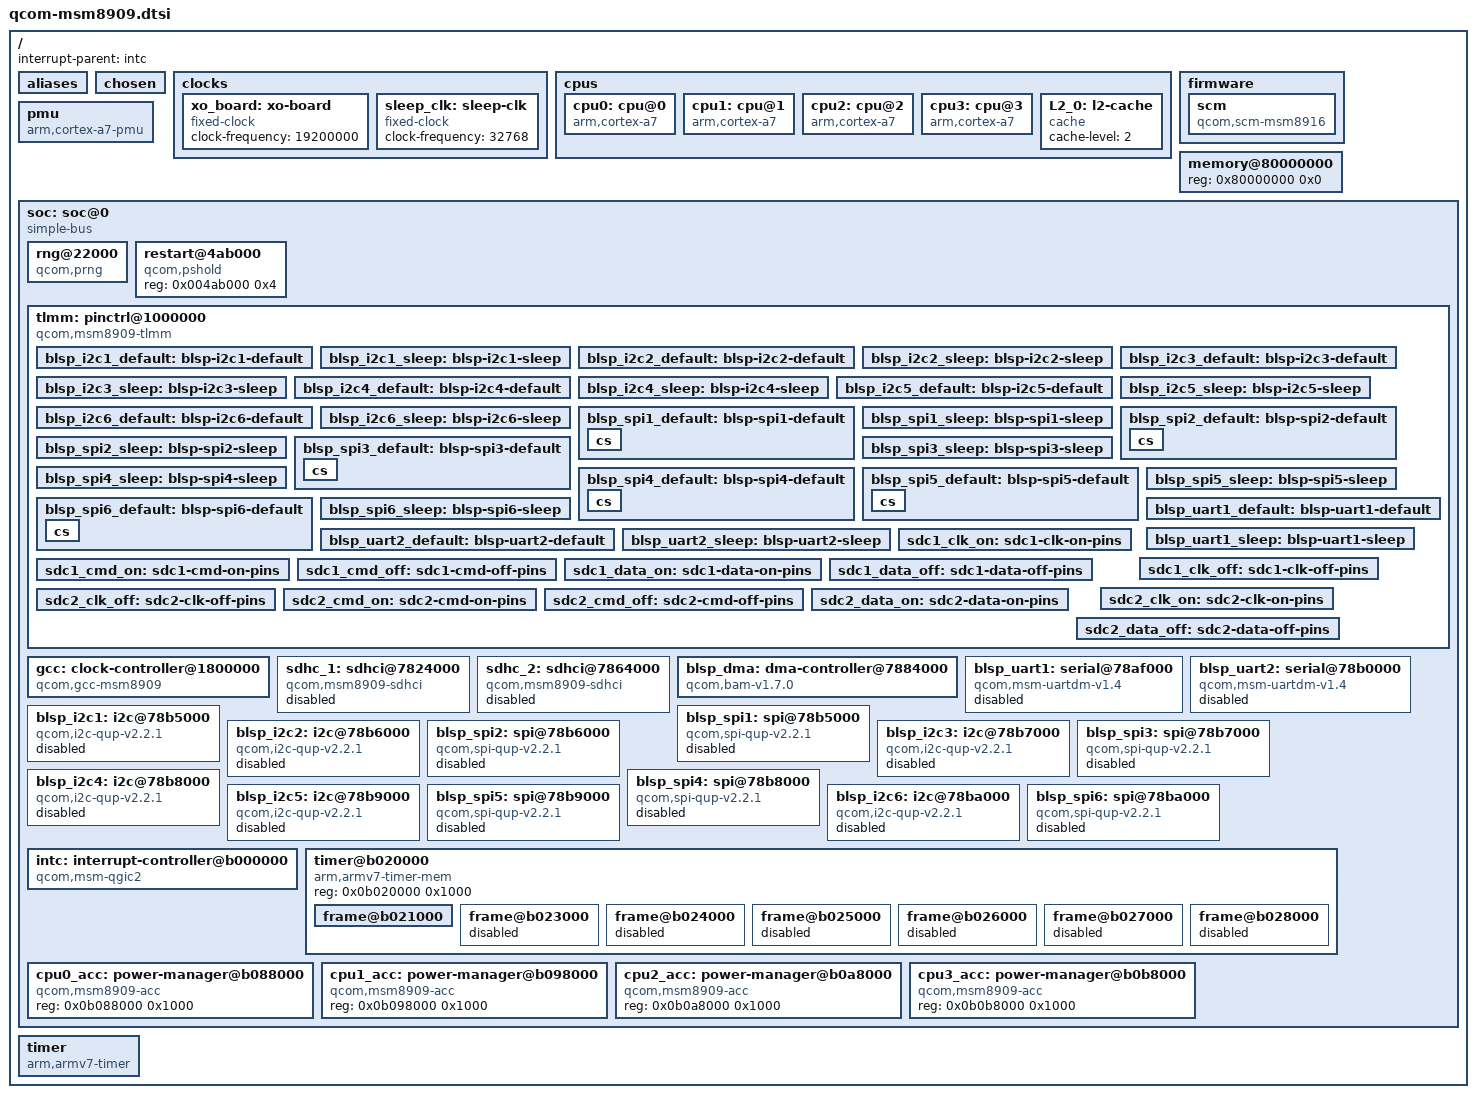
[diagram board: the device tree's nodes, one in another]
// SPDX-License-Identifier: GPL-2.0-only
/*
 * Copyright (c) 2014-2019, The Linux Foundation. All rights reserved.
 */
/dts-v1/;

#include <dt-bindings/clock/qcom,gcc-msm8909.h>
#include <dt-bindings/gpio/gpio.h>
#include <dt-bindings/interrupt-controller/arm-gic.h>

/ {
	#address-cells = <1>;
	#size-cells = <1>;
	interrupt-parent = <&intc>;

	aliases {
		mmc0 = &sdhc_1; /* SDC1 eMMC slot */
		mmc1 = &sdhc_2; /* SDC2 SD card slot */
	};

	chosen { };

	clocks {
		xo_board: xo-board {
			compatible = "fixed-clock";
			#clock-cells = <0>;
			clock-frequency = <19200000>;
		};

		sleep_clk: sleep-clk {
			compatible = "fixed-clock";
			#clock-cells = <0>;
			clock-frequency = <32768>;
		};
	};

	cpus {
		#address-cells = <1>;
		#size-cells = <0>;

		cpu0: cpu@0 {
			device_type = "cpu";
			compatible = "arm,cortex-a7";
			reg = <0x0>;
			next-level-cache = <&L2_0>;
			enable-method = "qcom,msm8909-smp";
			qcom,acc = <&cpu0_acc>;
		};

		cpu1: cpu@1 {
			device_type = "cpu";
			compatible = "arm,cortex-a7";
			reg = <0x1>;
			next-level-cache = <&L2_0>;
			enable-method = "qcom,msm8909-smp";
			qcom,acc = <&cpu1_acc>;
		};

		cpu2: cpu@2 {
			device_type = "cpu";
			compatible = "arm,cortex-a7";
			reg = <0x2>;
			next-level-cache = <&L2_0>;
			enable-method = "qcom,msm8909-smp";
			qcom,acc = <&cpu2_acc>;
		};

		cpu3: cpu@3 {
			device_type = "cpu";
			compatible = "arm,cortex-a7";
			reg = <0x3>;
			next-level-cache = <&L2_0>;
			enable-method = "qcom,msm8909-smp";
			qcom,acc = <&cpu3_acc>;
		};

		L2_0: l2-cache {
			compatible = "cache";
			cache-level = <2>;
		};
	};

	firmware {
		scm: scm {
			compatible = "qcom,scm-msm8916", "qcom,scm";
			clocks = <&gcc GCC_CRYPTO_CLK>,
				 <&gcc GCC_CRYPTO_AXI_CLK>,
				 <&gcc GCC_CRYPTO_AHB_CLK>;
			clock-names = "core", "bus", "iface";
			qcom,dload-mode = <&tcsr 0x6100>;
		};
	};

	memory@80000000 {
		device_type = "memory";
		/* We expect the bootloader to fill in the reg */
		reg = <0x80000000 0x0>;
	};

	pmu {
		compatible = "arm,cortex-a7-pmu";
		interrupts = <GIC_PPI 7 (GIC_CPU_MASK_SIMPLE(4) | IRQ_TYPE_LEVEL_HIGH)>;
	};

	soc: soc@0 {
		compatible = "simple-bus";
		#address-cells = <1>;
		#size-cells = <1>;
		ranges;

		rng@22000 {
			compatible = "qcom,prng";
			reg = <0x00022000 0x200>;
			clocks = <&gcc GCC_PRNG_AHB_CLK>;
			clock-names = "core";
		};

		restart@4ab000 {
			compatible = "qcom,pshold";
			reg = <0x004ab000 0x4>;
		};

		tlmm: pinctrl@1000000 {
			compatible = "qcom,msm8909-tlmm";
			reg = <0x01000000 0x300000>;
			interrupts = <GIC_SPI 208 IRQ_TYPE_LEVEL_HIGH>;
			gpio-controller;
			#gpio-cells = <2>;
			gpio-ranges = <&tlmm 0 0 117>;
			interrupt-controller;
			#interrupt-cells = <2>;

			blsp_i2c1_default: blsp-i2c1-default {
				pins = "gpio6", "gpio7";
				function = "blsp_i2c1";

				drive-strength = <2>;
				bias-disable;
			};

			blsp_i2c1_sleep: blsp-i2c1-sleep {
				pins = "gpio6", "gpio7";
				function = "gpio";

				drive-strength = <2>;
				bias-disable;
			};

			blsp_i2c2_default: blsp-i2c2-default {
				pins = "gpio111", "gpio112";
				function = "blsp_i2c2";

				drive-strength = <2>;
				bias-disable;
			};

			blsp_i2c2_sleep: blsp-i2c2-sleep {
				pins = "gpio111", "gpio112";
				function = "gpio";

				drive-strength = <2>;
				bias-disable;
			};

			blsp_i2c3_default: blsp-i2c3-default {
				pins = "gpio29", "gpio30";
				function = "blsp_i2c3";

				drive-strength = <2>;
				bias-disable;
			};

			blsp_i2c3_sleep: blsp-i2c3-sleep {
				pins = "gpio29", "gpio30";
				function = "gpio";

				drive-strength = <2>;
				bias-disable;
			};

			blsp_i2c4_default: blsp-i2c4-default {
				pins = "gpio14", "gpio15";
				function = "blsp_i2c4";

				drive-strength = <2>;
				bias-disable;
			};

			blsp_i2c4_sleep: blsp-i2c4-sleep {
				pins = "gpio14", "gpio15";
				function = "gpio";

				drive-strength = <2>;
				bias-disable;
			};

			blsp_i2c5_default: blsp-i2c5-default {
				pins = "gpio18", "gpio19";
				function = "blsp_i2c5";

				drive-strength = <2>;
				bias-disable;
			};

			blsp_i2c5_sleep: blsp-i2c5-sleep {
				pins = "gpio18", "gpio19";
				function = "gpio";

				drive-strength = <2>;
				bias-disable;
			};

			blsp_i2c6_default: blsp-i2c6-default {
				pins = "gpio10", "gpio11";
				function = "blsp_i2c6";

				drive-strength = <2>;
				bias-disable;
			};

			blsp_i2c6_sleep: blsp-i2c6-sleep {
				pins = "gpio10", "gpio11";
				function = "gpio";

				drive-strength = <2>;
				bias-disable;
			};

			blsp_spi1_default: blsp-spi1-default {
				pins = "gpio4", "gpio5", "gpio7";
				function = "blsp_spi1";

				drive-strength = <12>;
				bias-disable;

				cs {
					pins = "gpio6";
					function = "gpio";

					drive-strength = <2>;
					bias-disable;
					output-high;
				};
			};

			blsp_spi1_sleep: blsp-spi1-sleep {
				pins = "gpio4", "gpio5", "gpio6", "gpio7";
				function = "gpio";

				drive-strength = <2>;
				bias-pull-down;
			};

			blsp_spi2_default: blsp-spi2-default {
				pins = "gpio20", "gpio21", "gpio112";
				function = "blsp_spi2";

				drive-strength = <12>;
				bias-disable;

				cs {
					pins = "gpio111";
					function = "gpio";

					drive-strength = <2>;
					bias-disable;
					output-high;
				};
			};

			blsp_spi2_sleep: blsp-spi2-sleep {
				pins = "gpio20", "gpio21", "gpio111", "gpio112";
				function = "gpio";

				drive-strength = <2>;
				bias-pull-down;
			};

			blsp_spi3_default: blsp-spi3-default {
				pins = "gpio0", "gpio1", "gpio3";
				function = "blsp_spi3";

				drive-strength = <12>;
				bias-disable;

				cs {
					pins = "gpio2";
					function = "gpio";

					drive-strength = <2>;
					bias-disable;
					output-high;
				};
			};

			blsp_spi3_sleep: blsp-spi3-sleep {
				pins = "gpio0", "gpio1", "gpio2", "gpio3";
				function = "gpio";

				drive-strength = <2>;
				bias-pull-down;
			};

			blsp_spi4_default: blsp-spi4-default {
				pins = "gpio12", "gpio13", "gpio15";
				function = "blsp_spi4";

				drive-strength = <12>;
				bias-disable;

				cs {
					pins = "gpio14";
					function = "gpio";

					drive-strength = <2>;
					bias-disable;
					output-high;
				};
			};

			blsp_spi4_sleep: blsp-spi4-sleep {
				pins = "gpio12", "gpio13", "gpio14", "gpio15";
				function = "gpio";

				drive-strength = <2>;
				bias-pull-down;
			};

			blsp_spi5_default: blsp-spi5-default {
				pins = "gpio16", "gpio17", "gpio19";
				function = "blsp_spi5";

				drive-strength = <12>;
				bias-disable;

				cs {
					pins = "gpio18";
					function = "gpio";

					drive-strength = <2>;
					bias-disable;
					output-high;
				};
			};

			blsp_spi5_sleep: blsp-spi5-sleep {
				pins = "gpio16", "gpio17", "gpio18", "gpio19";
				function = "gpio";

				drive-strength = <2>;
				bias-pull-down;
			};

			blsp_spi6_default: blsp-spi6-default {
				pins = "gpio8", "gpio9", "gpio11";
				function = "blsp_spi6";

				drive-strength = <12>;
				bias-disable;

				cs {
					pins = "gpio10";
					function = "gpio";

					drive-strength = <2>;
					bias-disable;
					output-high;
				};
			};

			blsp_spi6_sleep: blsp-spi6-sleep {
				pins = "gpio8", "gpio9", "gpio10", "gpio11";
				function = "gpio";

				drive-strength = <2>;
				bias-pull-down;
			};

			blsp_uart1_default: blsp-uart1-default {
				pins = "gpio4", "gpio5";
				function = "blsp_uart1";

				drive-strength = <2>;
				bias-disable;
			};

			blsp_uart1_sleep: blsp-uart1-sleep {
				pins = "gpio4", "gpio5";
				function = "gpio";

				drive-strength = <2>;
				bias-pull-down;
			};

			blsp_uart2_default: blsp-uart2-default {
				pins = "gpio20", "gpio21";
				function = "blsp_uart2";

				drive-strength = <2>;
				bias-disable;
			};

			blsp_uart2_sleep: blsp-uart2-sleep {
				pins = "gpio20", "gpio21";
				function = "gpio";

				drive-strength = <2>;
				bias-pull-down;
			};

			sdc1_clk_on: sdc1-clk-on-pins {
				pins = "sdc1_clk";
				bias-disable;
				drive-strength = <16>;
			};

			sdc1_clk_off: sdc1-clk-off-pins {
				pins = "sdc1_clk";
				bias-disable;
				drive-strength = <2>;
			};

			sdc1_cmd_on: sdc1-cmd-on-pins {
				pins = "sdc1_cmd";
				bias-disable;
				drive-strength = <10>;
			};

			sdc1_cmd_off: sdc1-cmd-off-pins {
				pins = "sdc1_cmd";
				bias-disable;
				drive-strength = <2>;
			};

			sdc1_data_on: sdc1-data-on-pins {
				pins = "sdc1_data";
				bias-pull-up;
				drive-strength = <10>;
			};

			sdc1_data_off: sdc1-data-off-pins {
				pins = "sdc1_data";
				bias-pull-up;
				drive-strength = <2>;
			};

			sdc2_clk_on: sdc2-clk-on-pins {
				pins = "sdc2_clk";
				drive-strength = <16>;
				bias-disable;
			};

			sdc2_clk_off: sdc2-clk-off-pins {
				pins = "sdc2_clk";
				bias-disable;
				drive-strength = <2>;
			};

			sdc2_cmd_on: sdc2-cmd-on-pins {
				pins = "sdc2_cmd";
				bias-pull-up;
				drive-strength = <10>;
			};

			sdc2_cmd_off: sdc2-cmd-off-pins {
				pins = "sdc2_cmd";
				bias-pull-up;
				drive-strength = <2>;
			};

			sdc2_data_on: sdc2-data-on-pins {
				pins = "sdc2_data";
				bias-pull-up;
				drive-strength = <10>;
			};

			sdc2_data_off: sdc2-data-off-pins {
				pins = "sdc2_data";
				bias-pull-up;
				drive-strength = <2>;
			};
		};

		gcc: clock-controller@1800000 {
			compatible = "qcom,gcc-msm8909";
			reg = <0x01800000 0x80000>;
			#clock-cells = <1>;
			#reset-cells = <1>;
			#power-domain-cells = <1>;
			clocks = <&xo_board>, <&sleep_clk>, <0>, <0>;
			clock-names = "xo", "sleep_clk", "dsi0pll", "dsi0pllbyte";
		};

		sdhc_1: sdhci@7824000 {
			compatible = "qcom,msm8909-sdhci", "qcom,sdhci-msm-v4";
			reg = <0x07824900 0x11c>, <0x07824000 0x800>;
			reg-names = "hc_mem", "core_mem";

			interrupts = <GIC_SPI 123 IRQ_TYPE_LEVEL_HIGH>,
				     <GIC_SPI 138 IRQ_TYPE_LEVEL_HIGH>;
			interrupt-names = "hc_irq", "pwr_irq";
			clocks = <&gcc GCC_SDCC1_APPS_CLK>,
				 <&gcc GCC_SDCC1_AHB_CLK>,
				 <&xo_board>;
			clock-names = "core", "iface", "xo";

			pinctrl-names = "default", "sleep";
			pinctrl-0 = <&sdc1_clk_on &sdc1_cmd_on &sdc1_data_on>;
			pinctrl-1 = <&sdc1_clk_off &sdc1_cmd_off &sdc1_data_off>;

			mmc-hs200-1_8v;
			mmc-ddr-1_8v;
			bus-width = <8>;
			non-removable;
			status = "disabled";
		};

		sdhc_2: sdhci@7864000 {
			compatible = "qcom,msm8909-sdhci", "qcom,sdhci-msm-v4";
			reg = <0x07864900 0x11c>, <0x07864000 0x800>;
			reg-names = "hc_mem", "core_mem";

			interrupts = <GIC_SPI 125 IRQ_TYPE_LEVEL_HIGH>,
				     <GIC_SPI 221 IRQ_TYPE_LEVEL_HIGH>;
			interrupt-names = "hc_irq", "pwr_irq";
			clocks = <&gcc GCC_SDCC2_APPS_CLK>,
				 <&gcc GCC_SDCC2_AHB_CLK>,
				 <&xo_board>;
			clock-names = "core", "iface", "xo";

			pinctrl-names = "default", "sleep";
			pinctrl-0 = <&sdc2_clk_on &sdc2_cmd_on &sdc2_data_on>;
			pinctrl-1 = <&sdc2_clk_off &sdc2_cmd_off &sdc2_data_off>;

			bus-width = <4>;
			status = "disabled";
		};

		blsp_dma: dma-controller@7884000 {
			compatible = "qcom,bam-v1.7.0";
			reg = <0x07884000 0x23000>;
			interrupts = <GIC_SPI 238 IRQ_TYPE_LEVEL_HIGH>;
			clocks = <&gcc GCC_BLSP1_AHB_CLK>;
			clock-names = "bam_clk";
			#dma-cells = <1>;
			qcom,ee = <0>;
		};

		blsp_uart1: serial@78af000 {
			compatible = "qcom,msm-uartdm-v1.4", "qcom,msm-uartdm";
			reg = <0x078af000 0x200>;
			interrupts = <GIC_SPI 107 IRQ_TYPE_LEVEL_HIGH>;
			clocks = <&gcc GCC_BLSP1_UART1_APPS_CLK>,
				 <&gcc GCC_BLSP1_AHB_CLK>;
			clock-names = "core", "iface";
			dmas = <&blsp_dma 0>, <&blsp_dma 1>;
			dma-names = "tx", "rx";
			pinctrl-names = "default", "sleep";
			pinctrl-0 = <&blsp_uart1_default>;
			pinctrl-1 = <&blsp_uart1_sleep>;
			status = "disabled";
		};

		blsp_uart2: serial@78b0000 {
			compatible = "qcom,msm-uartdm-v1.4", "qcom,msm-uartdm";
			reg = <0x078b0000 0x200>;
			interrupts = <GIC_SPI 108 IRQ_TYPE_LEVEL_HIGH>;
			clocks = <&gcc GCC_BLSP1_UART2_APPS_CLK>,
				 <&gcc GCC_BLSP1_AHB_CLK>;
			clock-names = "core", "iface";
			dmas = <&blsp_dma 2>, <&blsp_dma 3>;
			dma-names = "tx", "rx";
			pinctrl-names = "default", "sleep";
			pinctrl-0 = <&blsp_uart2_default>;
			pinctrl-1 = <&blsp_uart2_sleep>;
			status = "disabled";
		};

		blsp_i2c1: i2c@78b5000 {
			compatible = "qcom,i2c-qup-v2.2.1";
			reg = <0x078b5000 0x500>;
			interrupts = <GIC_SPI 95 IRQ_TYPE_LEVEL_HIGH>;
			clocks = <&gcc GCC_BLSP1_QUP1_I2C_APPS_CLK>,
				 <&gcc GCC_BLSP1_AHB_CLK>;
			clock-names = "core", "iface";
			dmas = <&blsp_dma 4>, <&blsp_dma 5>;
			dma-names = "tx", "rx";
			pinctrl-names = "default", "sleep";
			pinctrl-0 = <&blsp_i2c1_default>;
			pinctrl-1 = <&blsp_i2c1_sleep>;
			#address-cells = <1>;
			#size-cells = <0>;
			status = "disabled";
		};

		blsp_spi1: spi@78b5000 {
			compatible = "qcom,spi-qup-v2.2.1";
			reg = <0x078b5000 0x500>;
			interrupts = <GIC_SPI 95 IRQ_TYPE_LEVEL_HIGH>;
			clocks = <&gcc GCC_BLSP1_QUP1_SPI_APPS_CLK>,
				 <&gcc GCC_BLSP1_AHB_CLK>;
			clock-names = "core", "iface";
			dmas = <&blsp_dma 4>, <&blsp_dma 5>;
			dma-names = "tx", "rx";
			pinctrl-names = "default", "sleep";
			pinctrl-0 = <&blsp_spi1_default>;
			pinctrl-1 = <&blsp_spi1_sleep>;
			#address-cells = <1>;
			#size-cells = <0>;
			status = "disabled";
		};

		blsp_i2c2: i2c@78b6000 {
			compatible = "qcom,i2c-qup-v2.2.1";
			reg = <0x078b6000 0x500>;
			interrupts = <GIC_SPI 96 IRQ_TYPE_LEVEL_HIGH>;
			clocks = <&gcc GCC_BLSP1_QUP2_I2C_APPS_CLK>,
				 <&gcc GCC_BLSP1_AHB_CLK>;
			clock-names = "core", "iface";
			dmas = <&blsp_dma 6>, <&blsp_dma 7>;
			dma-names = "tx", "rx";
			pinctrl-names = "default", "sleep";
			pinctrl-0 = <&blsp_i2c2_default>;
			pinctrl-1 = <&blsp_i2c2_sleep>;
			#address-cells = <1>;
			#size-cells = <0>;
			status = "disabled";
		};

		blsp_spi2: spi@78b6000 {
			compatible = "qcom,spi-qup-v2.2.1";
			reg = <0x078b6000 0x500>;
			interrupts = <GIC_SPI 96 IRQ_TYPE_LEVEL_HIGH>;
			clocks = <&gcc GCC_BLSP1_QUP2_SPI_APPS_CLK>,
				 <&gcc GCC_BLSP1_AHB_CLK>;
			clock-names = "core", "iface";
			dmas = <&blsp_dma 6>, <&blsp_dma 7>;
			dma-names = "tx", "rx";
			pinctrl-names = "default", "sleep";
			pinctrl-0 = <&blsp_spi2_default>;
			pinctrl-1 = <&blsp_spi2_sleep>;
			#address-cells = <1>;
			#size-cells = <0>;
			status = "disabled";
		};

		blsp_i2c3: i2c@78b7000 {
			compatible = "qcom,i2c-qup-v2.2.1";
			reg = <0x078b7000 0x500>;
			interrupts = <GIC_SPI 97 IRQ_TYPE_LEVEL_HIGH>;
			clocks = <&gcc GCC_BLSP1_QUP3_I2C_APPS_CLK>,
				 <&gcc GCC_BLSP1_AHB_CLK>;
			clock-names = "core", "iface";
			dmas = <&blsp_dma 8>, <&blsp_dma 9>;
			dma-names = "tx", "rx";
			pinctrl-names = "default", "sleep";
			pinctrl-0 = <&blsp_i2c3_default>;
			pinctrl-1 = <&blsp_i2c3_sleep>;
			#address-cells = <1>;
			#size-cells = <0>;
			status = "disabled";
		};

		blsp_spi3: spi@78b7000 {
			compatible = "qcom,spi-qup-v2.2.1";
			reg = <0x078b7000 0x500>;
			interrupts = <GIC_SPI 97 IRQ_TYPE_LEVEL_HIGH>;
			clocks = <&gcc GCC_BLSP1_QUP3_SPI_APPS_CLK>,
				 <&gcc GCC_BLSP1_AHB_CLK>;
			clock-names = "core", "iface";
			dmas = <&blsp_dma 8>, <&blsp_dma 9>;
			dma-names = "tx", "rx";
			pinctrl-names = "default", "sleep";
			pinctrl-0 = <&blsp_spi3_default>;
			pinctrl-1 = <&blsp_spi3_sleep>;
			#address-cells = <1>;
			#size-cells = <0>;
			status = "disabled";
		};

		blsp_i2c4: i2c@78b8000 {
			compatible = "qcom,i2c-qup-v2.2.1";
			reg = <0x078b8000 0x500>;
			interrupts = <GIC_SPI 98 IRQ_TYPE_LEVEL_HIGH>;
			clocks = <&gcc GCC_BLSP1_QUP4_I2C_APPS_CLK>,
				 <&gcc GCC_BLSP1_AHB_CLK>;
			clock-names = "core", "iface";
			dmas = <&blsp_dma 10>, <&blsp_dma 11>;
			dma-names = "tx", "rx";
			pinctrl-names = "default", "sleep";
			pinctrl-0 = <&blsp_i2c4_default>;
			pinctrl-1 = <&blsp_i2c4_sleep>;
			#address-cells = <1>;
			#size-cells = <0>;
			status = "disabled";
		};

		blsp_spi4: spi@78b8000 {
			compatible = "qcom,spi-qup-v2.2.1";
			reg = <0x078b8000 0x500>;
			interrupts = <GIC_SPI 98 IRQ_TYPE_LEVEL_HIGH>;
			clocks = <&gcc GCC_BLSP1_QUP4_SPI_APPS_CLK>,
				 <&gcc GCC_BLSP1_AHB_CLK>;
			clock-names = "core", "iface";
			dmas = <&blsp_dma 10>, <&blsp_dma 11>;
			dma-names = "tx", "rx";
			pinctrl-names = "default", "sleep";
			pinctrl-0 = <&blsp_spi4_default>;
			pinctrl-1 = <&blsp_spi4_sleep>;
			#address-cells = <1>;
			#size-cells = <0>;
			status = "disabled";
		};

		blsp_i2c5: i2c@78b9000 {
			compatible = "qcom,i2c-qup-v2.2.1";
			reg = <0x078b9000 0x500>;
			interrupts = <GIC_SPI 99 IRQ_TYPE_LEVEL_HIGH>;
			clocks = <&gcc GCC_BLSP1_QUP5_I2C_APPS_CLK>,
				 <&gcc GCC_BLSP1_AHB_CLK>;
			clock-names = "core", "iface";
			dmas = <&blsp_dma 12>, <&blsp_dma 13>;
			dma-names = "tx", "rx";
			pinctrl-names = "default", "sleep";
			pinctrl-0 = <&blsp_i2c5_default>;
			pinctrl-1 = <&blsp_i2c5_sleep>;
			#address-cells = <1>;
			#size-cells = <0>;
			status = "disabled";
		};

		blsp_spi5: spi@78b9000 {
			compatible = "qcom,spi-qup-v2.2.1";
			reg = <0x078b9000 0x500>;
			interrupts = <GIC_SPI 99 IRQ_TYPE_LEVEL_HIGH>;
			clocks = <&gcc GCC_BLSP1_QUP5_SPI_APPS_CLK>,
				 <&gcc GCC_BLSP1_AHB_CLK>;
			clock-names = "core", "iface";
			dmas = <&blsp_dma 12>, <&blsp_dma 13>;
			dma-names = "tx", "rx";
			pinctrl-names = "default", "sleep";
			pinctrl-0 = <&blsp_spi5_default>;
			pinctrl-1 = <&blsp_spi5_sleep>;
			#address-cells = <1>;
			#size-cells = <0>;
			status = "disabled";
		};

		blsp_i2c6: i2c@78ba000 {
			compatible = "qcom,i2c-qup-v2.2.1";
			reg = <0x078ba000 0x500>;
			interrupts = <GIC_SPI 100 IRQ_TYPE_LEVEL_HIGH>;
			clocks = <&gcc GCC_BLSP1_QUP6_I2C_APPS_CLK>,
				 <&gcc GCC_BLSP1_AHB_CLK>;
			clock-names = "core", "iface";
			dmas = <&blsp_dma 14>, <&blsp_dma 15>;
			dma-names = "tx", "rx";
			pinctrl-names = "default", "sleep";
			pinctrl-0 = <&blsp_i2c6_default>;
			pinctrl-1 = <&blsp_i2c6_sleep>;
			#address-cells = <1>;
			#size-cells = <0>;
			status = "disabled";
		};

		blsp_spi6: spi@78ba000 {
			compatible = "qcom,spi-qup-v2.2.1";
			reg = <0x078ba000 0x500>;
			interrupts = <GIC_SPI 100 IRQ_TYPE_LEVEL_HIGH>;
			clocks = <&gcc GCC_BLSP1_QUP6_SPI_APPS_CLK>,
				 <&gcc GCC_BLSP1_AHB_CLK>;
			clock-names = "core", "iface";
			dmas = <&blsp_dma 14>, <&blsp_dma 15>;
			dma-names = "tx", "rx";
			pinctrl-names = "default", "sleep";
			pinctrl-0 = <&blsp_spi6_default>;
			pinctrl-1 = <&blsp_spi6_sleep>;
			#address-cells = <1>;
			#size-cells = <0>;
			status = "disabled";
		};

		intc: interrupt-controller@b000000 {
			compatible = "qcom,msm-qgic2";
			reg = <0x0b000000 0x1000>,
			      <0x0b002000 0x1000>;
			interrupt-controller;
			#interrupt-cells = <3>;
		};

		timer@b020000 {
			compatible = "arm,armv7-timer-mem";
			reg = <0x0b020000 0x1000>;
			#address-cells = <1>;
			#size-cells = <1>;
			ranges;

			frame@b021000 {
				reg = <0x0b021000 0x1000>, <0x0b022000 0x1000>;
				interrupts = <GIC_SPI 8 IRQ_TYPE_LEVEL_HIGH>,
					     <GIC_SPI 7 IRQ_TYPE_LEVEL_HIGH>;
				frame-number = <0>;
			};

			frame@b023000 {
				reg = <0x0b023000 0x1000>;
				interrupts = <GIC_SPI 9 IRQ_TYPE_LEVEL_HIGH>;
				frame-number = <1>;
				status = "disabled";
			};

			frame@b024000 {
				reg = <0x0b024000 0x1000>;
				interrupts = <GIC_SPI 10 IRQ_TYPE_LEVEL_HIGH>;
				frame-number = <2>;
				status = "disabled";
			};

			frame@b025000 {
				reg = <0x0b025000 0x1000>;
				interrupts = <GIC_SPI 11 IRQ_TYPE_LEVEL_HIGH>;
				frame-number = <3>;
				status = "disabled";
			};

			frame@b026000 {
				reg = <0x0b026000 0x1000>;
				interrupts = <GIC_SPI 12 IRQ_TYPE_LEVEL_HIGH>;
				frame-number = <4>;
				status = "disabled";
			};

			frame@b027000 {
				reg = <0x0b027000 0x1000>;
				interrupts = <GIC_SPI 13 IRQ_TYPE_LEVEL_HIGH>;
				frame-number = <5>;
				status = "disabled";
			};

			frame@b028000 {
				reg = <0x0b028000 0x1000>;
				interrupts = <GIC_SPI 14 IRQ_TYPE_LEVEL_HIGH>;
				frame-number = <6>;
				status = "disabled";
			};
		};

		cpu0_acc: power-manager@b088000 {
			compatible = "qcom,msm8909-acc";
			reg = <0x0b088000 0x1000>;
		};
		cpu1_acc: power-manager@b098000 {
			compatible = "qcom,msm8909-acc";
			reg = <0x0b098000 0x1000>;
		};
		cpu2_acc: power-manager@b0a8000 {
			compatible = "qcom,msm8909-acc";
			reg = <0x0b0a8000 0x1000>;
		};
		cpu3_acc: power-manager@b0b8000 {
			compatible = "qcom,msm8909-acc";
			reg = <0x0b0b8000 0x1000>;
		};
	};

	timer {
		compatible = "arm,armv7-timer";
		interrupts = <GIC_PPI 2 (GIC_CPU_MASK_SIMPLE(4) | IRQ_TYPE_LEVEL_LOW)>,
			     <GIC_PPI 3 (GIC_CPU_MASK_SIMPLE(4) | IRQ_TYPE_LEVEL_LOW)>,
			     <GIC_PPI 4 (GIC_CPU_MASK_SIMPLE(4) | IRQ_TYPE_LEVEL_LOW)>,
			     <GIC_PPI 1 (GIC_CPU_MASK_SIMPLE(4) | IRQ_TYPE_LEVEL_LOW)>;
	};
};
